# HDSC_HC32F146JX register map
Vendor: HDSC Co.Ltd; Series: ARMCM0P; File version: 1.2
CPU: CM0 r0p0, little endian, no MPU, no FPU, 3 interrupt priority bits
Registers are 8-bit, read-write, reset 0x0 unless marked. A register's access mark holds for its fields unless they carry their own. Offsets are from the block's base; [hi:lo] are bit positions; {n}, {i} and the like mark numbered series.

## HWWDT
Base 0x40011000
0x00 WDT_LD 32-bit reset 0xFFFF
0x04 WDT_VL 32-bit ro
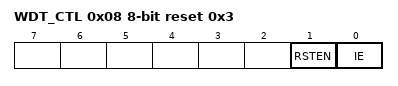
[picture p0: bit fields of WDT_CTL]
0x08 WDT_CTL reset 0x3
  [1] RSTEN, [0] IE
0x0C WDT_CLR
0x10 WDT_STA ro
  [0] STA
0x14 WDT_LCK 32-bit reset 0x1

## IRQC
Base 0x40031000
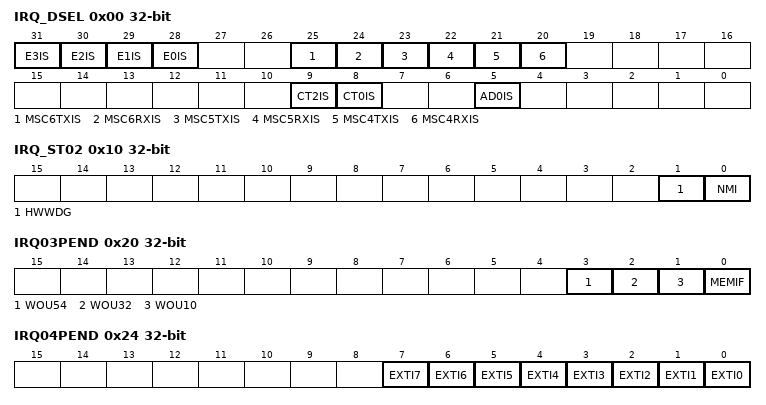
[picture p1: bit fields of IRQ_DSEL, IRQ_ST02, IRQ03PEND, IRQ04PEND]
0x00 IRQ_DSEL 32-bit
  [n+28] E{n}IS (n=0..3), [25] MSC6TXIS, [24] MSC6RXIS, [23] MSC5TXIS, [22] MSC5RXIS, [21] MSC4TXIS, [20] MSC4RXIS, [9] CT2IS, [8] CT0IS, [5] AD0IS
0x10 IRQ_ST02 32-bit ro
  [1] HWWDG, [0] NMI
0x14 IRQ00PEND 32-bit ro
  [0] AFDI
0x18 IRQ01PEND 32-bit ro
  [0] SWWDG
0x1C IRQ02PEND 32-bit ro
  [0] LVD
0x20 IRQ03PEND 32-bit ro
  [3] WOU54, [2] WOU32, [1] WOU10, [0] MEMIF
0x24 IRQ04PEND 32-bit ro
  [n] EXTI{n} (n=0..7)
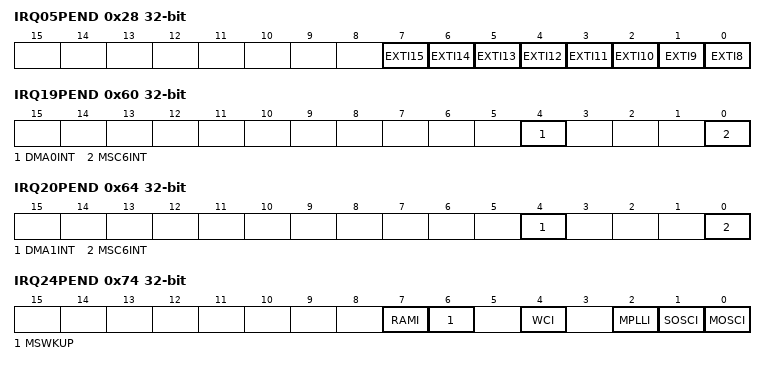
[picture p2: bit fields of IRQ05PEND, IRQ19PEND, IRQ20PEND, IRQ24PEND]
0x28 IRQ05PEND 32-bit ro
  [n-8] EXTI{n} (n=8..15)
0x2C IRQ06PEND 32-bit ro
  [1:0] DT1
0x50 IRQ15PEND 32-bit ro
  [0] MSC4INT
0x54 IRQ16PEND 32-bit ro
  [1:0] MSC4INT
0x58 IRQ17PEND 32-bit ro
  [0] MSC5NT
0x5C IRQ18PEND 32-bit ro
  [1:0] MSC5INT
0x60 IRQ19PEND 32-bit ro
  [4] DMA0INT, [0] MSC6INT
0x64 IRQ20PEND 32-bit ro
  [4] DMA1INT, [0] MSC6INT
0x74 IRQ24PEND 32-bit ro
  [7] RAMI, [6] MSWKUP, [4] WCI, [2] MPLLI, [1] SOSCI, [0] MOSCI
0x78 IRQ25PEND 32-bit ro
  [4:0] ADCI
0x7C IRQ26PEND 32-bit ro
  [5] VCI
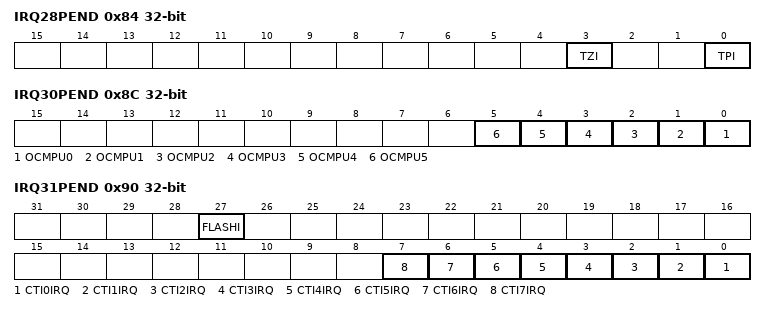
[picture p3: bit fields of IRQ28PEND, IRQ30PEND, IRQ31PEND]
0x84 IRQ28PEND 32-bit ro
  [3] TZI, [0] TPI
0x8C IRQ30PEND 32-bit ro
  [n] OCMPU{n} (n=0..5)
0x90 IRQ31PEND 32-bit ro
  [27] FLASHI, [n] CTI{n}IRQ (n=0..7)

## LCDC
Base 0x40032000
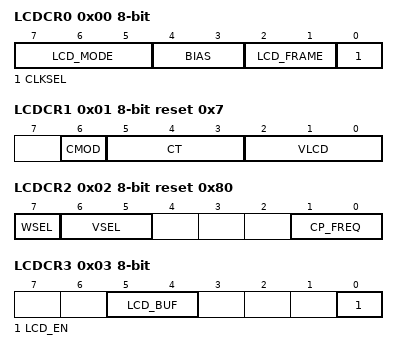
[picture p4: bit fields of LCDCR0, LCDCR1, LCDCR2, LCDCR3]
0x00 LCDCR0
  [7:5] LCD_MODE, [4:3] BIAS, [2:1] LCD_FRAME, [0] CLKSEL
0x01 LCDCR1 reset 0x7
  [6] CMOD, [5:3] CT, [2:0] VLCD
0x02 LCDCR2 reset 0x80
  [7] WSEL, [6:5] VSEL, [1:0] CP_FREQ
0x03 LCDCR3
  [5:4] LCD_BUF, [0] LCD_EN
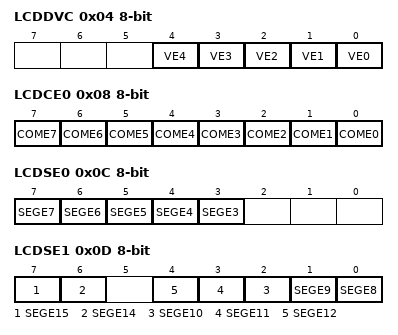
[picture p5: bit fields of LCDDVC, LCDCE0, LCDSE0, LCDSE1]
0x04 LCDDVC
  [n] VE{n} (n=0..4)
0x08 LCDCE0
  [n] COME{n} (n=0..7)
0x0C LCDSE0
  [n] SEGE{n} (n=3..7)
0x0D LCDSE1
  [7] SEGE15, [6] SEGE14, [n-8] SEGE{n} (n=8..12)
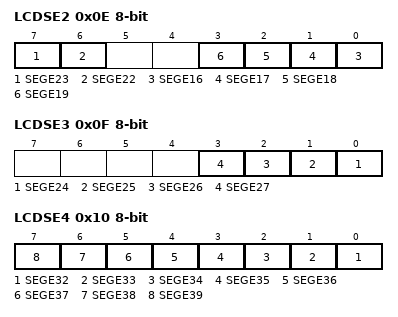
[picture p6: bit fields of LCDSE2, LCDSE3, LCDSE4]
0x0E LCDSE2
  [7] SEGE23, [6] SEGE22, [n-16] SEGE{n} (n=16..19)
0x0F LCDSE3
  [n-24] SEGE{n} (n=24..27)
0x10 LCDSE4
  [n-32] SEGE{n} (n=32..39)
{0x14+i} LCDRAM{i:02} (i=3..12)
{0x14+i} LCDRAM{i} (i=14..19)
{0x14+i} LCDRAM{i} (i=22..27)
{0x14+i} LCDRAM{i} (i=32..39)

## MSC4_I2C — desc MSC_I2C
Base 0x40037000
Same registers: MSC5_I2C 0x40037100, MSC6_I2C 0x40037200
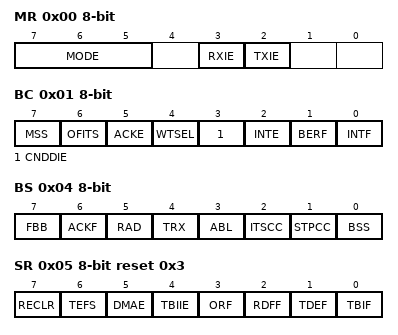
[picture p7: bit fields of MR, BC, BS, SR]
0x00 MR
  [7:5] MODE, [3] RXIE, [2] TXIE
0x01 BC
  [7] MSS, [6] OFITS, [5] ACKE, [4] WTSEL, [3] CNDDIE, [2] INTE, [1] BERF ro, [0] INTF
0x04 BS
  [7] FBB ro, [6] ACKF ro, [5] RAD ro, [4] TRX ro, [3] ABL ro, [2] ITSCC, [1] STPCC, [0] BSS ro
0x05 SR reset 0x3
  [7] RECLR, [6] TEFS, [5] DMAE, [4] TBIIE, [3] ORF ro, [2] RDFF ro, [1] TDEF ro, [0] TBIF ro
0x08 RXDR 16-bit ro (reset mask 0xFF)
0x08 TXDR 16-bit wo reset 0xFF (reset mask 0xFF)
0x0C BRS 16-bit
  [14:0] BRS
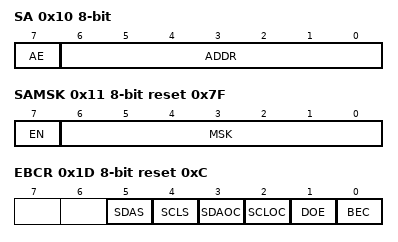
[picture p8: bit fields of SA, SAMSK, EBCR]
0x10 SA
  [7] AE, [6:0] ADDR
0x11 SAMSK reset 0x7F
  [7] EN, [6:0] MSK
0x1D EBCR reset 0xC
  [5] SDAS ro, [4] SCLS ro, [3] SDAOC, [2] SCLOC, [1] DOE, [0] BEC

## MSC4_SPI — desc MSC_SPI
Base 0x40037000; alternate view of MSC4_I2C
Same registers: MSC5_SPI 0x40037100 (alternate view of MSC5_I2C), MSC6_SPI 0x40037200 (alternate view of MSC6_I2C)
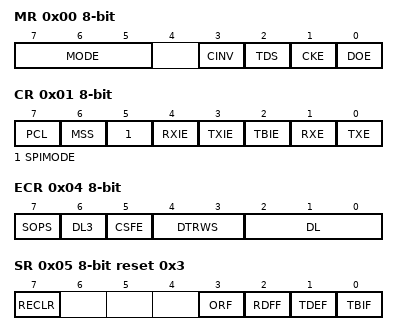
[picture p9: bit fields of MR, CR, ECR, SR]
0x00 MR
  [7:5] MODE, [3] CINV, [2] TDS, [1] CKE, [0] DOE
0x01 CR
  [7] PCL, [6] MSS, [5] SPIMODE, [4] RXIE, [3] TXIE, [2] TBIE, [1] RXE, [0] TXE
0x04 ECR
  [7] SOPS, [6] DL3, [5] CSFE, [4:3] DTRWS, [2:0] DL
0x05 SR reset 0x3
  [7] RECLR, [3] ORF ro, [2] RDFF ro, [1] TDEF ro, [0] TBIF ro
0x08 RXDR 16-bit ro
0x08 TXDR 16-bit wo reset 0xFFFF
0x0C BRS 16-bit (reset mask 0x7F)
  [14:0] BRS
0x1C CSTMG0
  [7:0] CSHDLY
0x1D CSTMG1
  [7:0] CSSDLY
0x20 CSTMG32 16-bit
  [15:0] CSDS
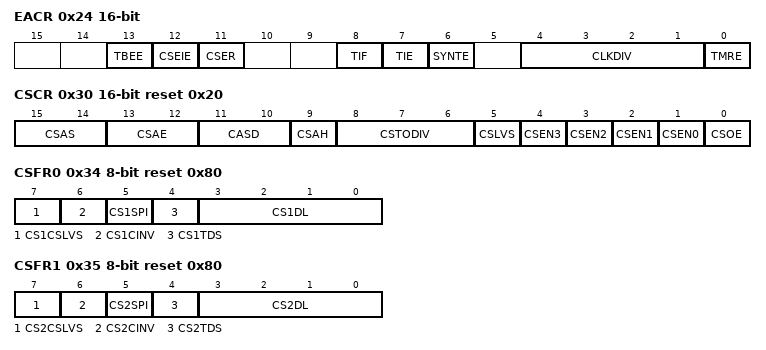
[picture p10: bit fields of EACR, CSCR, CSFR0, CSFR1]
0x24 EACR 16-bit
  [13] TBEE, [12] CSEIE, [11] CSER, [8] TIF, [7] TIE, [6] SYNTE, [4:1] CLKDIV, [0] TMRE
0x28 TMR 16-bit ro
0x2C TMC 16-bit
0x30 CSCR 16-bit reset 0x20
  [15:14] CSAS, [13:12] CSAE, [11:10] CASD ro, [9] CSAH, [8:6] CSTODIV, [5] CSLVS, [n+1] CSEN{n} (n=0..3), [0] CSOE
0x34 CSFR0 reset 0x80
  [7] CS1CSLVS, [6] CS1CINV, [5] CS1SPI, [4] CS1TDS, [3:0] CS1DL
0x35 CSFR1 reset 0x80
  [7] CS2CSLVS, [6] CS2CINV, [5] CS2SPI, [4] CS2TDS, [3:0] CS2DL
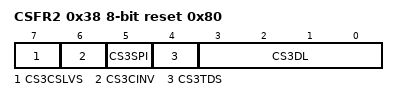
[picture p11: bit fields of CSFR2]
0x38 CSFR2 reset 0x80
  [7] CS3CSLVS, [6] CS3CINV, [5] CS3SPI, [4] CS3TDS, [3:0] CS3DL
0x3C TDTCNT0
0x3D TDTCNT1
0x40 TDTCNT2
0x41 TDTCNT3

## MSC4_UART — desc MSC_UART
Base 0x40037000; alternate view of MSC4_I2C
Same registers: MSC5_UART 0x40037100 (alternate view of MSC5_I2C), MSC6_UART 0x40037200 (alternate view of MSC6_I2C)
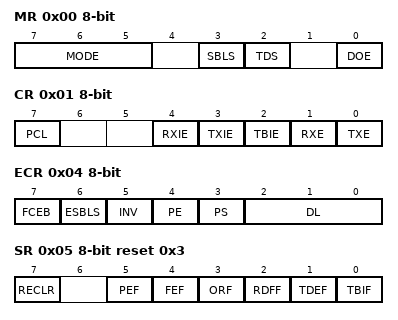
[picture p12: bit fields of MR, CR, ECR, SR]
0x00 MR
  [7:5] MODE, [3] SBLS, [2] TDS, [0] DOE
0x01 CR
  [7] PCL, [4] RXIE, [3] TXIE, [2] TBIE, [1] RXE, [0] TXE
0x04 ECR
  [7] FCEB, [6] ESBLS, [5] INV, [4] PE, [3] PS, [2:0] DL
0x05 SR reset 0x3
  [7] RECLR, [5] PEF ro, [4] FEF ro, [3] ORF ro, [2] RDFF ro, [1] TDEF ro, [0] TBIF ro
0x08 RXDR 16-bit ro (reset mask 0x1FF)
0x08 TXDR 16-bit wo reset 0x1FF (reset mask 0x1FF)
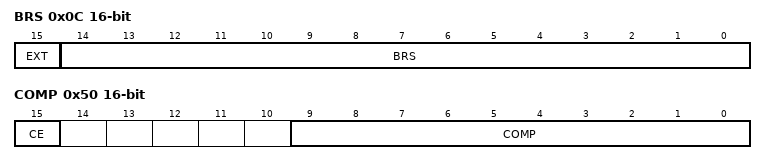
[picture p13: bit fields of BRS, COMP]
0x0C BRS 16-bit (reset mask 0xFF)
  [15] EXT, [14:0] BRS
0x50 COMP 16-bit
  [15] CE, [9:0] COMP

## MTB_DWT
Base 0xF0001000
0x00 ACSTR 32-bit
  [31:0] AC_ST
0x04 DCSTR 32-bit
  [31:0] DC_ST
0x08 MDCSTR 32-bit
  [31:0] MDC_ST
0x10 ACSPR 32-bit
  [31:0] AC_SP
0x14 DCSPR 32-bit
  [31:0] DC_SP
0x18 MDCSPR 32-bit
  [31:0] MDC_SP
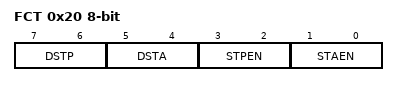
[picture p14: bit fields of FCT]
0x20 FCT
  [7:6] DSTP, [5:4] DSTA, [3:2] STPEN, [1:0] STAEN
{0xFC0+4i} PID{i} 32-bit ro (i=4..7)
  [31:0] PERID
{0xFE0+4i} PID{i} 32-bit ro (i=0..3)
  [31:0] PERID
{0xFF0+4i} CID{i} 32-bit ro (i=0..3)
  [31:0] CPNTID

## OPA0 — desc OPA
Base 0x4003C400
Same registers: OPA1 0x4003C480
0x00 OPA_CTL
  [0] OPA_EN

## OSC_CTL
Base 0x4002E000
0x00 HICR_TRMKEY 32-bit reset 0x1
0x04 HICR_FTRM 32-bit reset 0x64
  [7:0] CR4MFTRM
0x08 HICR_TTRM 32-bit reset 0x5
  [3:0] CR4MTTRM
0x10 HICR_FDIV reset 0x1
  [2:0] FDIV
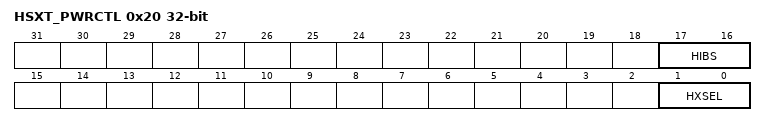
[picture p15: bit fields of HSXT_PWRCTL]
0x20 HSXT_PWRCTL 32-bit
  [17:16] HIBS, [1:0] HXSEL
0x30 LSXT_PWRCTL 32-bit reset 0x30000
  [18:16] LIBS

## PARITY
Base 0x4003C000
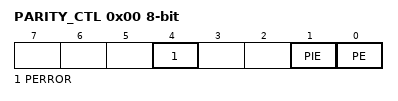
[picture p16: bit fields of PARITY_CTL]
0x00 PARITY_CTL
  [4] PERROR, [1] PIE, [0] PE
0x04 PARITY_ADDR 32-bit ro

## PCG
Base 0x4003C100
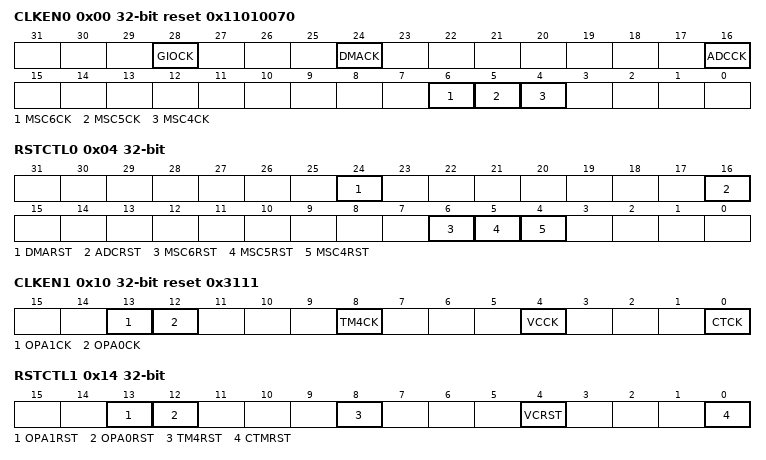
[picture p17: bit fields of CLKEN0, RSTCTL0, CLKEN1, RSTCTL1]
0x00 CLKEN0 32-bit reset 0x11010070
  [28] GIOCK, [24] DMACK, [16] ADCCK, [6] MSC6CK, [5] MSC5CK, [4] MSC4CK
0x04 RSTCTL0 32-bit
  [24] DMARST, [16] ADCRST, [6] MSC6RST, [5] MSC5RST, [4] MSC4RST
0x10 CLKEN1 32-bit reset 0x3111
  [13] OPA1CK, [12] OPA0CK, [8] TM4CK, [4] VCCK, [0] CTCK
0x14 RSTCTL1 32-bit
  [13] OPA1RST, [12] OPA0RST, [8] TM4RST, [4] VCRST, [0] CTMRST
0x20 CLKEN2 32-bit reset 0x10000
  [16] LCDCCK
0x24 RSTCTL2 32-bit
  [16] LCDCRST

## SWWDT
Base 0x40012000
0x00 WDT_LD 32-bit reset 0xFFFFFFFF
0x04 WDT_VL 32-bit ro reset 0xFFFFFFFF
0x08 WDT_CTL
  [4] WDM, [3:2] TMWD, [1] RSTEN, [0] IE
0x0C WDT_INTCLR 32-bit
0x10 WDT_STA ro
  [0] STA
0x18 WDT_MDC
  [0] TRG
0xC00 WDT_LCK 32-bit

## UID
Base 0x40000100
0x00 UIDR0 32-bit ro
  [31:0] UID
0x04 UIDR1 32-bit ro
  [31:0] UID
0x08 UIDR2 32-bit ro
  [15:0] UID

## VC
Base 0x4003C300
0x00 VC_CTL1 reset 0x18
  [4:3] VC_COMPSL, [2] VC_NMODE, [1] VC_OUT ro, [0] VC_EN
0x04 VC_CTL2 16-bit
  [11] VC_HYS_SEL, [10] VCIF, [9] VCIE, [8] VC2PT, [7] VCINT_HIGH, [6:5] VCINT_EDGE, [3:1] VC_RESPONSE, [0] VC_FILTER_EN
0x08 VC_CTL3
  [1] VC_TM2G, [0] VC_TM0G

## WSUNIT
Base 0x40035000
0x00 LVD1_SET 32-bit
  [24] LVD1_EN, [16] LVD1_SRST, [12:8] LVD1_SVHD, [4:0] LVD1_SVHR
0x04 LVD_INT_STR 32-bit ro
  [16] LVD2_IF, [0] LVD1_IF
0x08 LVD_CLR 32-bit
  [16] LVD2_CLR, [0] LVD1_CLR
0x10 LVD2_SET 32-bit
  [24] LVD2_EN, [16] LVD2_SRST, [12:8] LVD2_SVHD, [4:0] LVD2_SVHR
{0x6FF+i} BUR{i:02} (i=1..16)
